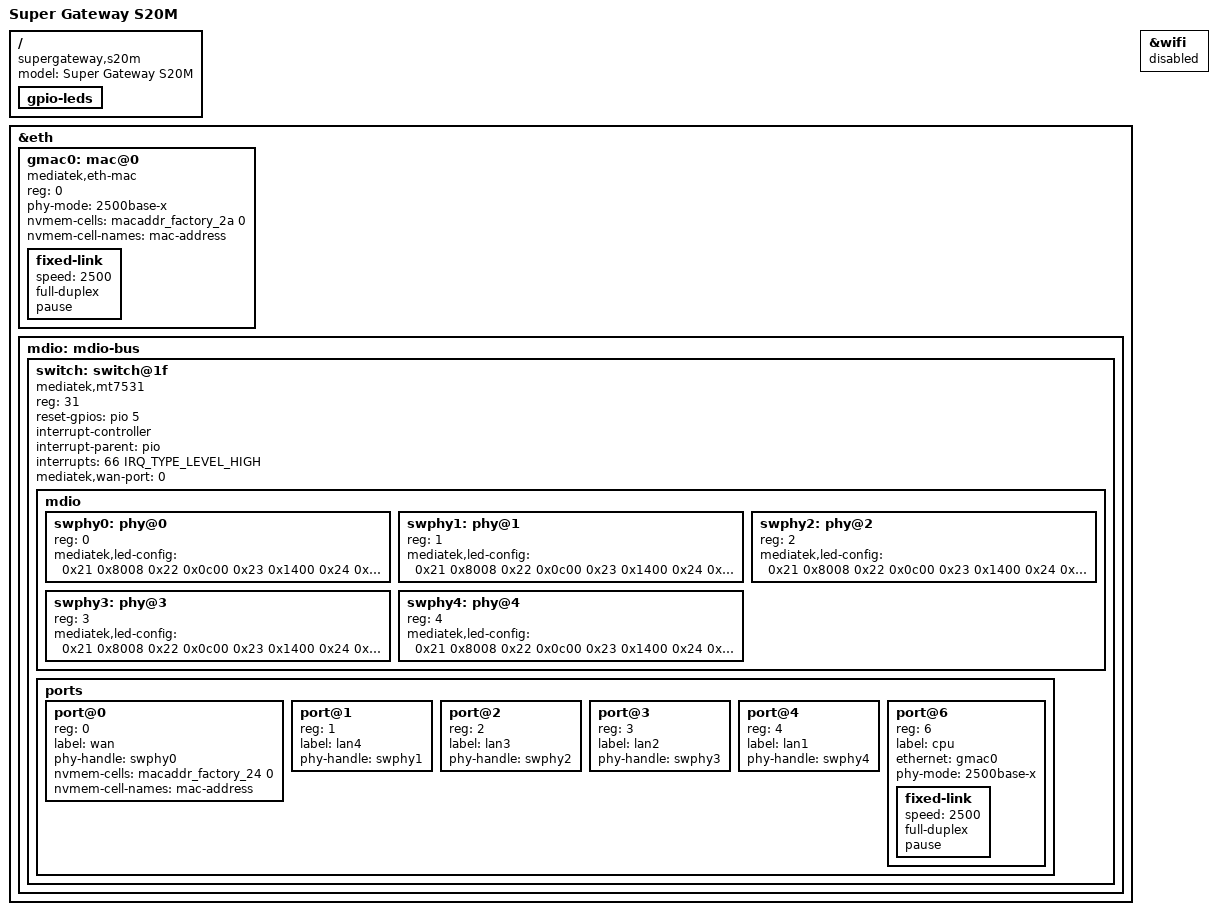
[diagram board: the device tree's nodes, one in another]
// SPDX-License-Identifier: GPL-2.0-or-later OR MIT

/dts-v1/;
#include "mt7986a-supergateway-s20-common.dtsi"

/ {
	model = "Super Gateway S20M";
	compatible = "supergateway,s20m", "mediatek,mt7986a";

	gpio-leds {
		/delete-node/ wlan5g_led;
		/delete-node/ wlan2g_led;
	};
};

&eth {
	status = "okay";

	gmac0: mac@0 {
		compatible = "mediatek,eth-mac";
		reg = <0>;
		phy-mode = "2500base-x";
		nvmem-cells = <&macaddr_factory_2a 0>;
		nvmem-cell-names = "mac-address";

		fixed-link {
			speed = <2500>;
			full-duplex;
			pause;
		};
	};

	mdio: mdio-bus {
		#address-cells = <1>;
		#size-cells = <0>;

		switch: switch@1f {
			compatible = "mediatek,mt7531";
			reg = <31>;
			reset-gpios = <&pio 5 GPIO_ACTIVE_HIGH>;
			interrupt-controller;
			#interrupt-cells = <1>;
			interrupt-parent = <&pio>;
			interrupts = <66 IRQ_TYPE_LEVEL_HIGH>;
			mediatek,wan-port = <0>;

			mdio {
				#address-cells = <1>;
				#size-cells = <0>;

				swphy0: phy@0 {
					reg = <0>;

					mediatek,led-config = <
						0x21 0x8008 /* BASIC_CTRL */
						0x22 0x0c00 /* ON_DURATION */
						0x23 0x1400 /* BLINK_DURATION */
						0x24 0xc000 /* LED0_ON_CTRL: activity only */
						0x25 0x003f /* LED0_BLINK_CTRL: all speeds */
						0x26 0xc001 /* LED1_ON_CTRL: 1000 Mbps link only */
						0x27 0x0000 /* LED1_BLINK_CTRL: steady link */
					>;
				};

				swphy1: phy@1 {
					reg = <1>;

					mediatek,led-config = <
						0x21 0x8008
						0x22 0x0c00
						0x23 0x1400
						0x24 0xc000
						0x25 0x003f
						0x26 0xc001
						0x27 0x0000
					>;
				};

				swphy2: phy@2 {
					reg = <2>;

					mediatek,led-config = <
						0x21 0x8008
						0x22 0x0c00
						0x23 0x1400
						0x24 0xc000
						0x25 0x003f
						0x26 0xc001
						0x27 0x0000
					>;
				};

				swphy3: phy@3 {
					reg = <3>;

					mediatek,led-config = <
						0x21 0x8008
						0x22 0x0c00
						0x23 0x1400
						0x24 0xc000
						0x25 0x003f
						0x26 0xc001
						0x27 0x0000
					>;
				};

				swphy4: phy@4 {
					reg = <4>;

					mediatek,led-config = <
						0x21 0x8008
						0x22 0x0c00
						0x23 0x1400
						0x24 0xc000
						0x25 0x003f
						0x26 0xc001
						0x27 0x0000
					>;
				};
			};

			ports {
				#address-cells = <1>;
				#size-cells = <0>;

				port@0 {
					reg = <0>;
					label = "wan";
					phy-handle = <&swphy0>;

					nvmem-cells = <&macaddr_factory_24 0>;
					nvmem-cell-names = "mac-address";
				};

				port@1 {
					reg = <1>;
					label = "lan4";
					phy-handle = <&swphy1>;
				};

				port@2 {
					reg = <2>;
					label = "lan3";
					phy-handle = <&swphy2>;
				};

				port@3 {
					reg = <3>;
					label = "lan2";
					phy-handle = <&swphy3>;
				};

				port@4 {
					reg = <4>;
					label = "lan1";
					phy-handle = <&swphy4>;
				};

				port@6 {
					reg = <6>;
					label = "cpu";
					ethernet = <&gmac0>;
					phy-mode = "2500base-x";

					fixed-link {
						speed = <2500>;
						full-duplex;
						pause;
					};
				};
			};
		};
	};
};

&wifi {
	status = "disabled";
};
